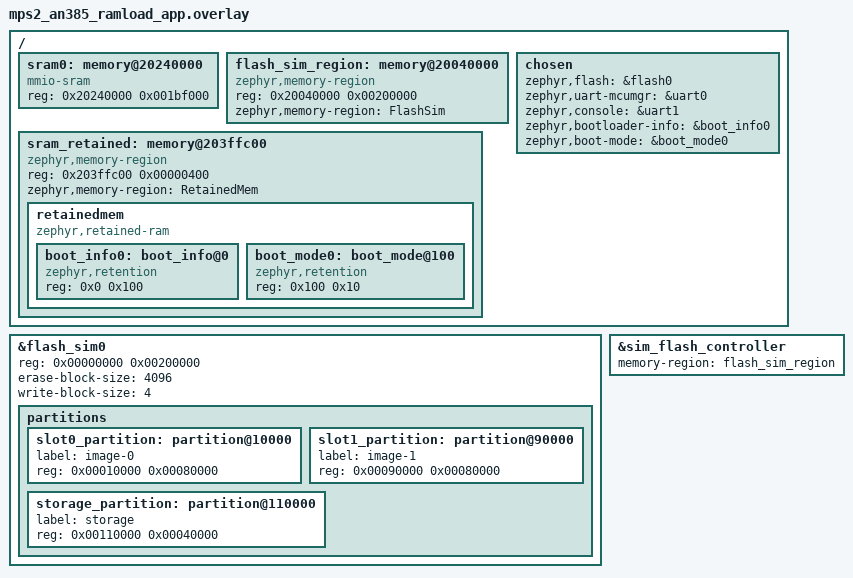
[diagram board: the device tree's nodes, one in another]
/*
 * Application image of the mps2/an385 RAM_LOAD MCUboot fixture. MCUboot copies
 * slot0 into SRAM and runs it from there (the flash simulator is not XIP-mapped
 * on mps2). Must agree with sysbuild/mcuboot_recovery.overlay.
 *
 * Like MCUboot, the app keeps logging and SMP on separate UARTs: SMP on uart0,
 * the console + log on uart1. So the whole lifecycle is observable on uart1 --
 * MCUboot's boot decision and then the app's own log -- while uart0 stays a
 * clean SMP channel for the client.
 *
 * SRAM (4 MB) is carved into non-overlapping regions plus a retained tail:
 *   0x20000000  256K  mcuboot runtime (.bss/stack while it loads the app)
 *   0x20040000  2M    FlashSim   -- the sim-flash backing store; a memory-region
 *                                   means the simulator is NOT erased at boot, so
 *                                   an uploaded slot0 survives a soft reset
 *   0x20240000  ~1.7M app RAM exec region (the imgtool load address)
 *   0x203ffc00  1K    RetainedMem -- MCUboot shared boot info + boot mode
 */
/delete-node/ &sram0;
/delete-node/ &storage_partition;

/ {
	sram0: memory@20240000 {
		compatible = "mmio-sram";
		reg = <0x20240000 0x001bf000>;	/* app RAM exec region (load addr 0x20240000) */
	};

	flash_sim_region: memory@20040000 {
		compatible = "zephyr,memory-region", "mmio-sram";
		reg = <0x20040000 0x00200000>;	/* 2 MB, holds the sim-flash mock storage */
		ranges = <0x0 0x20040000 0x00200000>;
		zephyr,memory-region = "FlashSim";
		status = "okay";
		#address-cells = <1>;
		#size-cells = <1>;
	};

	sram_retained: memory@203ffc00 {
		compatible = "zephyr,memory-region", "mmio-sram";
		reg = <0x203ffc00 0x00000400>;	/* 1 KB, outside all images' SRAM */
		ranges = <0x0 0x203ffc00 0x00000400>;
		zephyr,memory-region = "RetainedMem";
		status = "okay";
		#address-cells = <1>;
		#size-cells = <1>;

		retainedmem {
			compatible = "zephyr,retained-ram";
			status = "okay";
			ranges;
			#address-cells = <1>;
			#size-cells = <1>;

			boot_info0: boot_info@0 {
				compatible = "zephyr,retention";
				status = "okay";
				reg = <0x0 0x100>;
			};

			boot_mode0: boot_mode@100 {
				compatible = "zephyr,retention";
				status = "okay";
				reg = <0x100 0x10>;
			};
		};
	};

	chosen {
		zephyr,flash = &flash0;
		zephyr,uart-mcumgr = &uart0;	/* SMP channel */
		zephyr,console = &uart1;	/* app console + log, separate from SMP */
		/delete-property/ zephyr,code-partition;
		zephyr,bootloader-info = &boot_info0;
		zephyr,boot-mode = &boot_mode0;
	};
};

/* Slots + storage match the MCUboot image: same 0-based sim-flash offsets. */
&flash_sim0 {
	reg = <0x00000000 0x00200000>;	/* 2 MB, FlashSim backing store */
	erase-block-size = <4096>;
	write-block-size = <4>;

	partitions {
		slot0_partition: partition@10000 {
			label = "image-0";
			reg = <0x00010000 0x00080000>;	/* 512 KB -> SRAM 0x20050000 */
		};
		slot1_partition: partition@90000 {
			label = "image-1";
			reg = <0x00090000 0x00080000>;	/* 512 KB */
		};
		storage_partition: partition@110000 {
			label = "storage";
			reg = <0x00110000 0x00040000>;	/* 256 KB, for littlefs/settings */
		};
	};
};

/* Persist the sim-flash across reboot (no erase-at-start with a memory-region). */
&sim_flash_controller {
	memory-region = <&flash_sim_region>;
};
